# STM32H745_CM4 register map
File version: 2.5
CPU: CM4 r0p1, little endian, MPU, FPU, 4 interrupt priority bits
Registers are 32-bit, read-write, reset 0x0 unless marked. A register's access mark holds for its fields unless they carry their own. Offsets are from the block's base; [hi:lo] are bit positions; 'fields as' and 'values as' point back to an identical list.

## DMA2D
Base 0x52001000
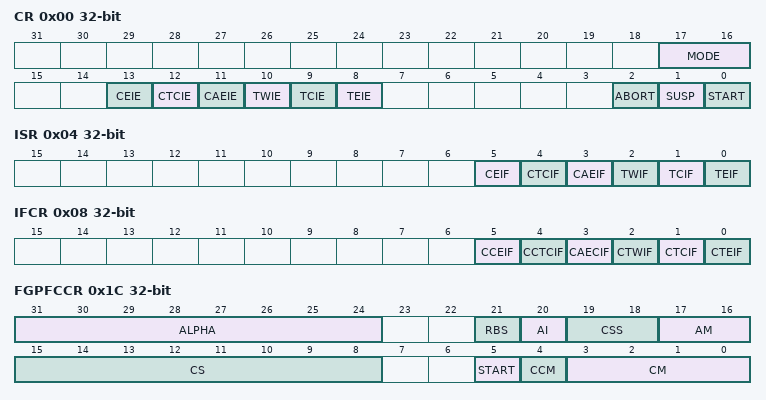
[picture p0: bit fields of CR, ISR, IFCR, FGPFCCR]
0x00 CR — DMA2D control register
  [17:16] MODE — DMA2D mode This bit is set and cleared by software. It cannot be modified while a transfer is ongoing.
    0=Memory-to-memory (FG fetch only); 1=MemoryToMemoryPFC (Memory-to-memory with PFC (FG fetch only with FG PFC active)); 2=MemoryToMemoryPFCBlending (Memory-to-memory with blending (FG and BG fetch with PFC and blending)); 3=RegisterToMemory
  [13] CEIE — Configuration Error Interrupt Enable This bit is set and cleared by software.
    0=Disabled (CE interrupt disabled); 1=Enabled (CE interrupt enabled)
  [12] CTCIE — CLUT transfer complete interrupt enable This bit is set and cleared by software.
    0=Disabled (CTC interrupt disabled); 1=Enabled (CTC interrupt enabled)
  [11] CAEIE — CLUT access error interrupt enable This bit is set and cleared by software.
    0=Disabled (CAE interrupt disabled); 1=Enabled (CAE interrupt enabled)
  [10] TWIE — Transfer watermark interrupt enable This bit is set and cleared by software.
    0=Disabled (TW interrupt disabled); 1=Enabled (TW interrupt enabled)
  [9] TCIE — Transfer complete interrupt enable This bit is set and cleared by software.
    0=Disabled (TC interrupt disabled); 1=Enabled (TC interrupt enabled)
  [8] TEIE — Transfer error interrupt enable This bit is set and cleared by software.
    0=Disabled (TE interrupt disabled); 1=Enabled (TE interrupt enabled)
  [2] ABORT — Abort This bit can be used to abort the current transfer. This bit is set by software and is automatically reset by hardware when the START bit is reset.
    1=AbortRequest (Transfer abort requested)
  [1] SUSP — Suspend This bit can be used to suspend the current transfer. This bit is set and reset by software. It is automatically reset by hardware when the START bit is reset.
    0=NotSuspended (Transfer not suspended); 1=Suspended (Transfer suspended)
  [0] START — Start This bit can be used to launch the DMA2D according to the parameters loaded in the various configuration registers
    1=Start (Launch the DMA2D)
0x04 ISR ro — DMA2D Interrupt Status Register
  [5] CEIF — Configuration error interrupt flag This bit is set when the START bit of DMA2D_CR, DMA2DFGPFCCR or DMA2D_BGPFCCR is set and a wrong configuration has been programmed.
  [4] CTCIF — CLUT transfer complete interrupt flag This bit is set when the CLUT copy from a system memory area to the internal DMA2D memory is complete.
  [3] CAEIF — CLUT access error interrupt flag This bit is set when the CPU accesses the CLUT while the CLUT is being automatically copied from a system memory to the internal DMA2D.
  [2] TWIF — Transfer watermark interrupt flag This bit is set when the last pixel of the watermarked line has been transferred.
  [1] TCIF — Transfer complete interrupt flag This bit is set when a DMA2D transfer operation is complete (data transfer only).
  [0] TEIF — Transfer error interrupt flag This bit is set when an error occurs during a DMA transfer (data transfer or automatic CLUT loading).
0x08 IFCR — DMA2D interrupt flag clear register
  [5] CCEIF — Clear configuration error interrupt flag Programming this bit to 1 clears the CEIF flag in the DMA2D_ISR register
    1=Clear the CEIF flag in the ISR register
  [4] CCTCIF — Clear CLUT transfer complete interrupt flag Programming this bit to 1 clears the CTCIF flag in the DMA2D_ISR register
    1=Clear the CTCIF flag in the ISR register
  [3] CAECIF — Clear CLUT access error interrupt flag Programming this bit to 1 clears the CAEIF flag in the DMA2D_ISR register
    1=Clear the CAEIF flag in the ISR register
  [2] CTWIF — Clear transfer watermark interrupt flag Programming this bit to 1 clears the TWIF flag in the DMA2D_ISR register
    1=Clear the TWIF flag in the ISR register
  [1] CTCIF — Clear transfer complete interrupt flag Programming this bit to 1 clears the TCIF flag in the DMA2D_ISR register
    1=Clear the TCIF flag in the ISR register
  [0] CTEIF — Clear Transfer error interrupt flag Programming this bit to 1 clears the TEIF flag in the DMA2D_ISR register
    1=Clear the TEIF flag in the ISR register
0x0C FGMAR — DMA2D foreground memory address register
  [31:0] MA — Memory address Address of the data used for the foreground image. This register can only be written when data transfers are disabled. Once the data transfer has started, this register is read-only. The address alignment must match the image format selected e.g. a 32-bit per pixel format must be 32-bit aligned, a 16-bit per pixel format must be 16-bit aligned and a 4-bit per pixel format must be 8-bit aligned.
0x10 FGOR — DMA2D foreground offset register
  [15:0] LO — Line offset Line offset used for the foreground expressed in pixel. This value is used to generate the address. It is added at the end of each line to determine the starting address of the next line. These bits can only be written when data transfers are disabled. Once a data transfer has started, they become read-only. If the image format is 4-bit per pixel, the line offset must be even.
0x14 BGMAR — DMA2D background memory address register
  [31:0] MA — Memory address Address of the data used for the background image. This register can only be written when data transfers are disabled. Once a data transfer has started, this register is read-only. The address alignment must match the image format selected e.g. a 32-bit per pixel format must be 32-bit aligned, a 16-bit per pixel format must be 16-bit aligned and a 4-bit per pixel format must be 8-bit aligned.
0x18 BGOR — DMA2D background offset register
  [15:0] LO — Line offset Line offset used for the background image (expressed in pixel). This value is used for the address generation. It is added at the end of each line to determine the starting address of the next line. These bits can only be written when data transfers are disabled. Once data transfer has started, they become read-only. If the image format is 4-bit per pixel, the line offset must be even.
0x1C FGPFCCR — DMA2D foreground PFC control register
  [31:24] ALPHA — Alpha value These bits define a fixed alpha channel value which can replace the original alpha value or be multiplied by the original alpha value according to the alpha mode selected through the AM[1:0] bits. These bits can only be written when data transfers are disabled. Once a transfer has started, they become read-only.
  [21] RBS — Red Blue Swap This bit allows to swap the R & B to support BGR or ABGR color formats. Once the transfer has started, this bit is read-only.
    0=Regular (No Red Blue Swap (RGB or ARGB)); 1=Swap (Red Blue Swap (BGR or ABGR))
  [20] AI — Alpha Inverted This bit inverts the alpha value. Once the transfer has started, this bit is read-only.
    0=RegularAlpha; 1=InvertedAlpha
  [19:18] CSS — Chroma Sub-Sampling These bits define the chroma sub-sampling mode for YCbCr color mode. Once the transfer has started, these bits are read-only. others: meaningless
  [17:16] AM — Alpha mode These bits select the alpha channel value to be used for the foreground image. They can only be written data the transfer are disabled. Once the transfer has started, they become read-only. other configurations are meaningless
    0=NoModify (No modification of alpha channel); 1=Replace with value in ALPHA[7:0]; 2=Multiply with value in ALPHA[7:0]
  [15:8] CS — CLUT size These bits define the size of the CLUT used for the foreground image. Once the CLUT transfer has started, this field is read-only. The number of CLUT entries is equal to CS[7:0] + 1.
  [5] START — Start This bit can be set to start the automatic loading of the CLUT. It is automatically reset: ** at the end of the transfer ** when the transfer is aborted by the user application by setting the ABORT bit in DMA2D_CR ** when a transfer error occurs ** when the transfer has not started due to a configuration error or another transfer operation already ongoing (data transfer or automatic background CLUT transfer).
    1=Start the automatic loading of the CLUT
  [4] CCM — CLUT color mode This bit defines the color format of the CLUT. It can only be written when the transfer is disabled. Once the CLUT transfer has started, this bit is read-only.
    0=ARGB8888 (CLUT color format ARGB8888); 1=RGB888 (CLUT color format RGB888)
  [3:0] CM — Color mode These bits defines the color format of the foreground image. They can only be written when data transfers are disabled. Once the transfer has started, they are read-only. others: meaningless
    0=ARGB8888 (Color mode ARGB8888); 1=RGB888 (Color mode RGB888); 2=RGB565 (Color mode RGB565); 3=ARGB1555 (Color mode ARGB1555); 4=ARGB4444 (Color mode ARGB4444); 5=L8 (Color mode L8); 6=AL44 (Color mode AL44); 7=AL88 (Color mode AL88); 8=L4 (Color mode L4); 9=A8 (Color mode A8); 10=A4 (Color mode A4); 11=YCbCr (Color mode YCbCr)
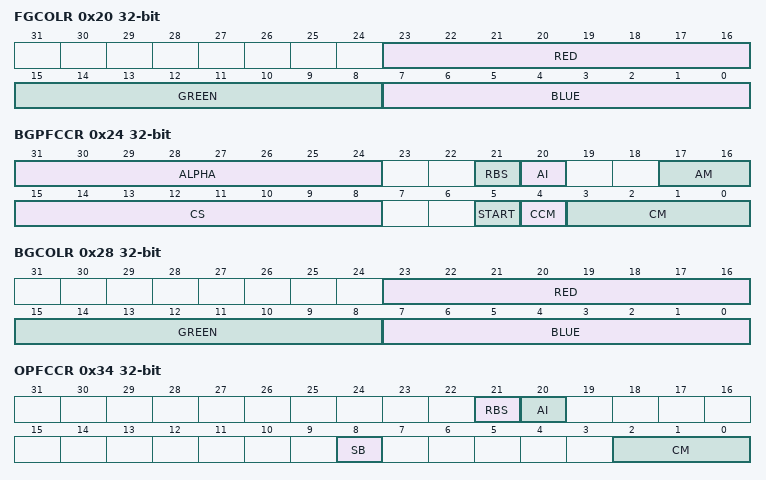
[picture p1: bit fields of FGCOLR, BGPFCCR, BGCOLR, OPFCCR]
0x20 FGCOLR — DMA2D foreground color register
  [23:16] RED — Red Value These bits defines the red value for the A4 or A8 mode of the foreground image. They can only be written when data transfers are disabled. Once the transfer has started, they are read-only.
  [15:8] GREEN — Green Value These bits defines the green value for the A4 or A8 mode of the foreground image. They can only be written when data transfers are disabled. Once the transfer has started, They are read-only.
  [7:0] BLUE — Blue Value These bits defines the blue value for the A4 or A8 mode of the foreground image. They can only be written when data transfers are disabled. Once the transfer has started, They are read-only.
0x24 BGPFCCR — DMA2D background PFC control register
  [31:24] ALPHA — Alpha value These bits define a fixed alpha channel value which can replace the original alpha value or be multiplied with the original alpha value according to the alpha mode selected with bits AM[1: 0]. These bits can only be written when data transfers are disabled. Once the transfer has started, they are read-only.
  [21] RBS — Red Blue Swap This bit allows to swap the R & B to support BGR or ABGR color formats. Once the transfer has started, this bit is read-only.
    values as FGPFCCR.RBS
  [20] AI — Alpha Inverted This bit inverts the alpha value. Once the transfer has started, this bit is read-only.
    0=RegularAlpha; 1=InvertedAlpha
  [17:16] AM — Alpha mode These bits define which alpha channel value to be used for the background image. These bits can only be written when data transfers are disabled. Once the transfer has started, they are read-only. others: meaningless
    values as FGPFCCR.AM
  [15:8] CS — CLUT size These bits define the size of the CLUT used for the BG. Once the CLUT transfer has started, this field is read-only. The number of CLUT entries is equal to CS[7:0] + 1.
  [5] START — Start This bit is set to start the automatic loading of the CLUT. This bit is automatically reset: ** at the end of the transfer ** when the transfer is aborted by the user application by setting the ABORT bit in the DMA2D_CR ** when a transfer error occurs ** when the transfer has not started due to a configuration error or another transfer operation already on going (data transfer or automatic BackGround CLUT transfer).
    1=Start the automatic loading of the CLUT
  [4] CCM — CLUT Color mode These bits define the color format of the CLUT. This register can only be written when the transfer is disabled. Once the CLUT transfer has started, this bit is read-only.
    values as FGPFCCR.CCM
  [3:0] CM — Color mode These bits define the color format of the foreground image. These bits can only be written when data transfers are disabled. Once the transfer has started, they are read-only. others: meaningless
    0=ARGB8888 (Color mode ARGB8888); 1=RGB888 (Color mode RGB888); 2=RGB565 (Color mode RGB565); 3=ARGB1555 (Color mode ARGB1555); 4=ARGB4444 (Color mode ARGB4444); 5=L8 (Color mode L8); 6=AL44 (Color mode AL44); 7=AL88 (Color mode AL88); 8=L4 (Color mode L4); 9=A8 (Color mode A8); 10=A4 (Color mode A4)
0x28 BGCOLR — DMA2D background color register
  [23:16] RED — Red Value These bits define the red value for the A4 or A8 mode of the background. These bits can only be written when data transfers are disabled. Once the transfer has started, they are read-only.
  [15:8] GREEN — Green Value These bits define the green value for the A4 or A8 mode of the background. These bits can only be written when data transfers are disabled. Once the transfer has started, they are read-only.
  [7:0] BLUE — Blue Value These bits define the blue value for the A4 or A8 mode of the background. These bits can only be written when data transfers are disabled. Once the transfer has started, they are read-only.
0x2C FGCMAR — DMA2D foreground CLUT memory address register
  [31:0] MA — Memory Address Address of the data used for the CLUT address dedicated to the foreground image. This register can only be written when no transfer is ongoing. Once the CLUT transfer has started, this register is read-only. If the foreground CLUT format is 32-bit, the address must be 32-bit aligned.
0x30 BGCMAR — DMA2D background CLUT memory address register
  [31:0] MA — Memory address Address of the data used for the CLUT address dedicated to the background image. This register can only be written when no transfer is on going. Once the CLUT transfer has started, this register is read-only. If the background CLUT format is 32-bit, the address must be 32-bit aligned.
0x34 OPFCCR — DMA2D output PFC control register
  [21] RBS — Red Blue Swap This bit allows to swap the R & B to support BGR or ABGR color formats. Once the transfer has started, this bit is read-only.
    values as FGPFCCR.RBS
  [20] AI — Alpha Inverted This bit inverts the alpha value. Once the transfer has started, this bit is read-only.
    0=RegularAlpha; 1=InvertedAlpha
  [8] SB — Swap Bytes
    0=Regular byte order; 1=SwapBytes (Bytes are swapped two by two)
  [2:0] CM — Color mode These bits define the color format of the output image. These bits can only be written when data transfers are disabled. Once the transfer has started, they are read-only. others: meaningless
    0=ARGB8888; 1=RGB888; 2=RGB565; 3=ARGB1555; 4=ARGB4444
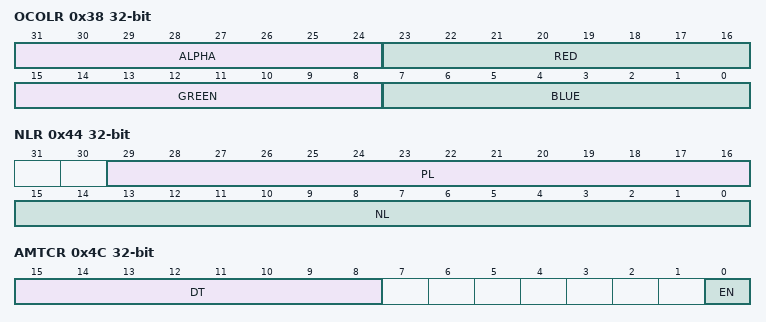
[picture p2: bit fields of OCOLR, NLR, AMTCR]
0x38 OCOLR — DMA2D output color register
  [31:24] ALPHA — Alpha Channel Value These bits define the alpha channel of the output color. These bits can only be written when data transfers are disabled. Once the transfer has started, they are read-only.
  [23:16] RED — Red Value These bits define the red value of the output image. These bits can only be written when data transfers are disabled. Once the transfer has started, they are read-only.
  [15:8] GREEN — Green Value These bits define the green value of the output image. These bits can only be written when data transfers are disabled. Once the transfer has started, they are read-only.
  [7:0] BLUE — Blue Value These bits define the blue value of the output image. These bits can only be written when data transfers are disabled. Once the transfer has started, they are read-only.
0x3C OMAR — DMA2D output memory address register
  [31:0] MA — Memory Address Address of the data used for the output FIFO. These bits can only be written when data transfers are disabled. Once the transfer has started, they are read-only. The address alignment must match the image format selected e.g. a 32-bit per pixel format must be 32-bit aligned and a 16-bit per pixel format must be 16-bit aligned.
0x40 OOR — DMA2D output offset register
  [15:0] LO — Line Offset Line offset used for the output (expressed in pixels). This value is used for the address generation. It is added at the end of each line to determine the starting address of the next line. These bits can only be written when data transfers are disabled. Once the transfer has started, they are read-only.
0x44 NLR — DMA2D number of line register
  [29:16] PL — Pixel per lines Number of pixels per lines of the area to be transferred. These bits can only be written when data transfers are disabled. Once the transfer has started, they are read-only. If any of the input image format is 4-bit per pixel, pixel per lines must be even.
  [15:0] NL — Number of lines Number of lines of the area to be transferred. These bits can only be written when data transfers are disabled. Once the transfer has started, they are read-only.
0x48 LWR — DMA2D line watermark register
  [15:0] LW — Line watermark These bits allow to configure the line watermark for interrupt generation. An interrupt is raised when the last pixel of the watermarked line has been transferred. These bits can only be written when data transfers are disabled. Once the transfer has started, they are read-only.
0x4C AMTCR — DMA2D AXI master timer configuration register
  [15:8] DT — Dead Time Dead time value in the AXI clock cycle inserted between two consecutive accesses on the AXI master port. These bits represent the minimum guaranteed number of cycles between two consecutive AXI accesses.
  [0] EN — Enable Enables the dead time functionality.
    0=Disabled AHB/AXI dead-time functionality; 1=Enabled AHB/AXI dead-time functionality
